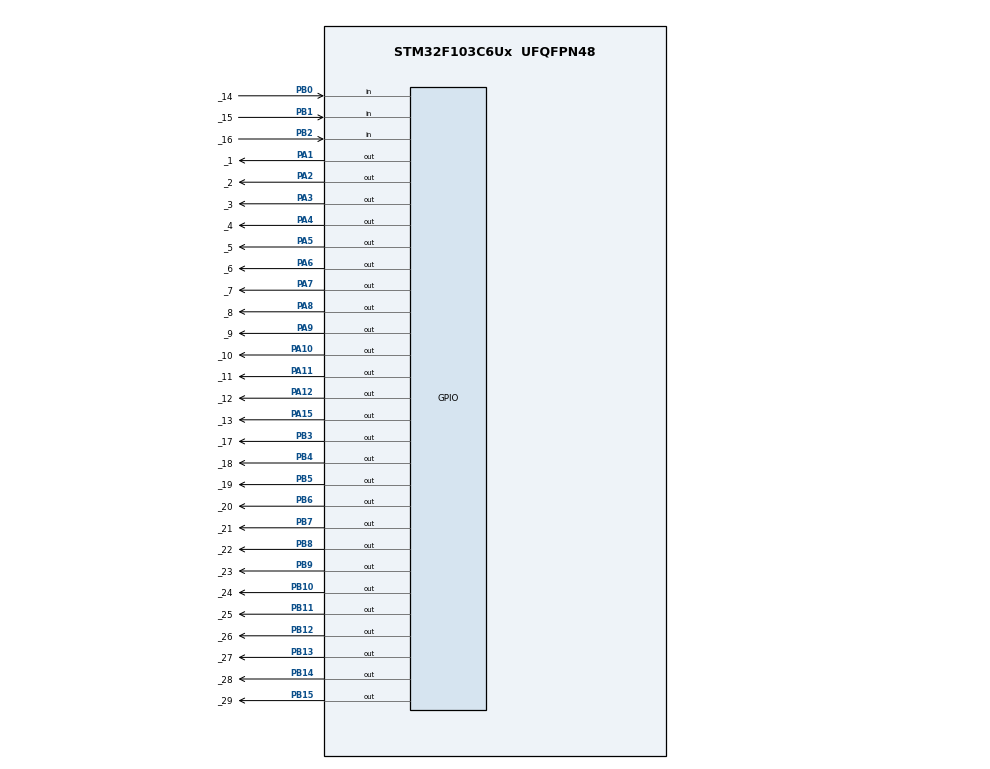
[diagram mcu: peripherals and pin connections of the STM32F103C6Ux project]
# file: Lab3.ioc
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Mcu.Family=STM32F1
Mcu.Name=STM32F103C6Ux
Mcu.Package=UFQFPN48
NVIC.PriorityGroup=NVIC_PRIORITYGROUP_4
NVIC.TIM2_IRQn=true\:0\:0\:false\:false\:true\:true\:true\:true
PA1.GPIO_Label=_1
PA1.Signal=GPIO_Output
PA10.GPIO_Label=_10
PA10.Signal=GPIO_Output
PA11.GPIO_Label=_11
PA11.Signal=GPIO_Output
PA12.GPIO_Label=_12
PA12.Signal=GPIO_Output
PA13.Mode=Serial_Wire
PA13.Signal=SYS_JTMS-SWDIO
PA14.Mode=Serial_Wire
PA14.Signal=SYS_JTCK-SWCLK
PA15.GPIO_Label=_13
PA15.Signal=GPIO_Output
PA2.GPIO_Label=_2
PA2.Signal=GPIO_Output
PA3.GPIO_Label=_3
PA3.Signal=GPIO_Output
PA4.GPIO_Label=_4
PA4.Signal=GPIO_Output
PA5.GPIO_Label=_5
PA5.Signal=GPIO_Output
PA6.GPIO_Label=_6
PA6.Signal=GPIO_Output
PA7.GPIO_Label=_7
PA7.Signal=GPIO_Output
PA8.GPIO_Label=_8
PA8.Signal=GPIO_Output
PA9.GPIO_Label=_9
PA9.Signal=GPIO_Output
PB0.GPIO_Label=_14
PB0.GPIO_PuPd=GPIO_PULLUP
PB0.Signal=GPIO_Input
PB1.GPIO_Label=_15
PB1.GPIO_PuPd=GPIO_PULLUP
PB1.Signal=GPIO_Input
PB10.GPIO_Label=_24
PB10.Signal=GPIO_Output
PB11.GPIO_Label=_25
PB11.Signal=GPIO_Output
PB12.GPIO_Label=_26
PB12.Signal=GPIO_Output
PB13.GPIO_Label=_27
PB13.Signal=GPIO_Output
PB14.GPIO_Label=_28
PB14.Signal=GPIO_Output
PB15.GPIO_Label=_29
PB15.Signal=GPIO_Output
PB2.GPIO_Label=_16
PB2.GPIO_PuPd=GPIO_PULLUP
PB2.Signal=GPIO_Input
PB3.GPIO_Label=_17
PB3.Signal=GPIO_Output
PB4.GPIO_Label=_18
PB4.Signal=GPIO_Output
PB5.GPIO_Label=_19
PB5.Signal=GPIO_Output
PB6.GPIO_Label=_20
PB6.Signal=GPIO_Output
PB7.GPIO_Label=_21
PB7.Signal=GPIO_Output
PB8.GPIO_Label=_22
PB8.Signal=GPIO_Output
PB9.GPIO_Label=_23
PB9.Signal=GPIO_Output
ProjectManager.HeapSize=0x200
ProjectManager.StackSize=0x400
ProjectManager.TargetToolchain=STM32CubeIDE
RCC.APB1Freq_Value=8000000
RCC.APB2Freq_Value=8000000
TIM2.Period=9
TIM2.Prescaler=7999
VP_TIM2_VS_ClockSourceINT.Mode=Internal
board=custom

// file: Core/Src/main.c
/* USER CODE BEGIN Header */
/**
  ******************************************************************************
  * @file           : main.c
  * @brief          : Main program body
  ******************************************************************************
  * @attention
  *
  * Copyright (c) 2025 STMicroelectronics.
  * All rights reserved.
  *
  * This software is licensed under terms that can be found in the LICENSE file
  * in the root directory of this software component.
  * If no LICENSE file comes with this software, it is provided AS-IS.
  *
  ******************************************************************************
  */
/* USER CODE END Header */
#include "main.h"

/* USER CODE BEGIN Includes */
#include "input_processing.h"
#include "fsm_traffic3_4.h"
#include "soft_timer.h"
#include "stm32f103c6.h"
#include "display_7seg.h"

/* USER CODE END Includes */

TIM_HandleTypeDef htim2;

void SystemClock_Config(void);
static void MX_GPIO_Init(void);
static void MX_TIM2_Init(void);

int main(void)
{

  /* MCU Configuration--------------------------------------------------------*/

  /* Reset of all peripherals, Initializes the Flash interface and the Systick. */
  HAL_Init();

  /* Configure the system clock */
  SystemClock_Config();

  /* Initialize all configured peripherals */
  MX_GPIO_Init();
  MX_TIM2_Init();
  /* USER CODE BEGIN 2 */
  HAL_TIM_Base_Start_IT(&htim2);

  // Initialize display system
  display_init();

  // Initialize FSM and timers
  fsm_traffic_init();
  setTimerLED_SYS(500 / TIMER_CYCLE_MS);  // LED_SYS blinks every 500ms
  setTimer1(1000 / TIMER_CYCLE_MS);       // 1 second timer for traffic countdown
  setTimer2(250 / TIMER_CYCLE_MS);        // 250ms timer for 2Hz LED blinking

  /* USER CODE END 2 */

  /* Infinite loop */
  while (1)
  {

    /* USER CODE BEGIN 3 */

    blinkLED_SYS_TIM(500);

    // Process button inputs
    fsm_for_input_processing();

    // Run traffic FSM
    fsm_traffic_run();
  }
  /* USER CODE END 3 */
}

void SystemClock_Config(void)
{
  RCC_OscInitTypeDef RCC_OscInitStruct = {0};
  RCC_ClkInitTypeDef RCC_ClkInitStruct = {0};

  /** Initializes the RCC Oscillators according to the specified parameters
  * in the RCC_OscInitTypeDef structure.
  */
  RCC_OscInitStruct.OscillatorType = RCC_OSCILLATORTYPE_HSI;
  RCC_OscInitStruct.HSIState = RCC_HSI_ON;
  RCC_OscInitStruct.HSICalibrationValue = RCC_HSICALIBRATION_DEFAULT;
  RCC_OscInitStruct.PLL.PLLState = RCC_PLL_NONE;
  if (HAL_RCC_OscConfig(&RCC_OscInitStruct) != HAL_OK)
  {
    Error_Handler();
  }

  /** Initializes the CPU, AHB and APB buses clocks
  */
  RCC_ClkInitStruct.ClockType = RCC_CLOCKTYPE_HCLK|RCC_CLOCKTYPE_SYSCLK
                              |RCC_CLOCKTYPE_PCLK1|RCC_CLOCKTYPE_PCLK2;
  RCC_ClkInitStruct.SYSCLKSource = RCC_SYSCLKSOURCE_HSI;
  RCC_ClkInitStruct.AHBCLKDivider = RCC_SYSCLK_DIV1;
  RCC_ClkInitStruct.APB1CLKDivider = RCC_HCLK_DIV1;
  RCC_ClkInitStruct.APB2CLKDivider = RCC_HCLK_DIV1;

  if (HAL_RCC_ClockConfig(&RCC_ClkInitStruct, FLASH_LATENCY_0) != HAL_OK)
  {
    Error_Handler();
  }
}

static void MX_TIM2_Init(void)
{

  TIM_ClockConfigTypeDef sClockSourceConfig = {0};
  TIM_MasterConfigTypeDef sMasterConfig = {0};

  htim2.Instance = TIM2;
  htim2.Init.Prescaler = 7999;
  htim2.Init.CounterMode = TIM_COUNTERMODE_UP;
  htim2.Init.Period = 9;
  htim2.Init.ClockDivision = TIM_CLOCKDIVISION_DIV1;
  htim2.Init.AutoReloadPreload = TIM_AUTORELOAD_PRELOAD_DISABLE;
  if (HAL_TIM_Base_Init(&htim2) != HAL_OK)
  {
    Error_Handler();
  }
  sClockSourceConfig.ClockSource = TIM_CLOCKSOURCE_INTERNAL;
  if (HAL_TIM_ConfigClockSource(&htim2, &sClockSourceConfig) != HAL_OK)
  {
    Error_Handler();
  }
  sMasterConfig.MasterOutputTrigger = TIM_TRGO_RESET;
  sMasterConfig.MasterSlaveMode = TIM_MASTERSLAVEMODE_DISABLE;
  if (HAL_TIMEx_MasterConfigSynchronization(&htim2, &sMasterConfig) != HAL_OK)
  {
    Error_Handler();
  }

}

static void MX_GPIO_Init(void)
{
  GPIO_InitTypeDef GPIO_InitStruct = {0};

  /* GPIO Ports Clock Enable */
  __HAL_RCC_GPIOA_CLK_ENABLE();
  __HAL_RCC_GPIOB_CLK_ENABLE();

  /*Configure GPIO pin Output Level */
  HAL_GPIO_WritePin(GPIOA, _1_Pin|_2_Pin|_3_Pin|_4_Pin
                          |_5_Pin|_6_Pin|_7_Pin|_8_Pin
                          |_9_Pin|_10_Pin|_11_Pin|_12_Pin
                          |_13_Pin, GPIO_PIN_RESET);

  /*Configure GPIO pin Output Level */
  HAL_GPIO_WritePin(GPIOB, _24_Pin|_25_Pin|_26_Pin|_27_Pin
                          |_28_Pin|_29_Pin|_17_Pin|_18_Pin
                          |_19_Pin|_20_Pin|_21_Pin|_22_Pin
                          |_23_Pin, GPIO_PIN_RESET);

  /*Configure GPIO pins : _1_Pin _2_Pin _3_Pin _4_Pin
                           _5_Pin _6_Pin _7_Pin _8_Pin
                           _9_Pin _10_Pin _11_Pin _12_Pin
                           _13_Pin */
  GPIO_InitStruct.Pin = _1_Pin|_2_Pin|_3_Pin|_4_Pin
                          |_5_Pin|_6_Pin|_7_Pin|_8_Pin
                          |_9_Pin|_10_Pin|_11_Pin|_12_Pin
                          |_13_Pin;
  GPIO_InitStruct.Mode = GPIO_MODE_OUTPUT_PP;
  GPIO_InitStruct.Pull = GPIO_NOPULL;
  GPIO_InitStruct.Speed = GPIO_SPEED_FREQ_LOW;
  HAL_GPIO_Init(GPIOA, &GPIO_InitStruct);

  /*Configure GPIO pins : _14_Pin _15_Pin _16_Pin */
  GPIO_InitStruct.Pin = _14_Pin|_15_Pin|_16_Pin;
  GPIO_InitStruct.Mode = GPIO_MODE_INPUT;
  GPIO_InitStruct.Pull = GPIO_PULLUP;
  HAL_GPIO_Init(GPIOB, &GPIO_InitStruct);

  /*Configure GPIO pins : _24_Pin _25_Pin _26_Pin _27_Pin
                           _28_Pin _29_Pin _17_Pin _18_Pin
                           _19_Pin _20_Pin _21_Pin _22_Pin
                           _23_Pin */
  GPIO_InitStruct.Pin = _24_Pin|_25_Pin|_26_Pin|_27_Pin
                          |_28_Pin|_29_Pin|_17_Pin|_18_Pin
                          |_19_Pin|_20_Pin|_21_Pin|_22_Pin
                          |_23_Pin;
  GPIO_InitStruct.Mode = GPIO_MODE_OUTPUT_PP;
  GPIO_InitStruct.Pull = GPIO_NOPULL;
  GPIO_InitStruct.Speed = GPIO_SPEED_FREQ_LOW;
  HAL_GPIO_Init(GPIOB, &GPIO_InitStruct);

}

void Error_Handler(void)
{
  __disable_irq();
  while (1)
  {
  }
}
